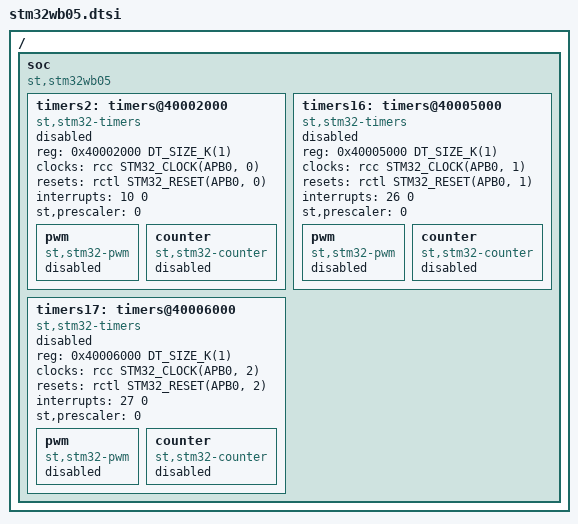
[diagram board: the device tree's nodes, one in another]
/*
 * Copyright (c) 2024 STMicroelectronics
 *
 * SPDX-License-Identifier: Apache-2.0
 */

#include <st/wb0/stm32wb0.dtsi>

/ {
	soc {
		compatible = "st,stm32wb05", "st,stm32wb0", "simple-bus";

		timers2: timers@40002000 {
			compatible = "st,stm32-timers";
			reg = <0x40002000 DT_SIZE_K(1)>;
			clocks = <&rcc STM32_CLOCK(APB0, 0)>;
			resets = <&rctl STM32_RESET(APB0, 0)>;
			interrupts = <10 0>;
			interrupt-names = "global";
			st,prescaler = <0>;
			status = "disabled";

			pwm {
				compatible = "st,stm32-pwm";
				status = "disabled";
				#pwm-cells = <3>;
			};

			counter {
				compatible = "st,stm32-counter";
				status = "disabled";
			};
		};

		timers16: timers@40005000 {
			compatible = "st,stm32-timers";
			reg = <0x40005000 DT_SIZE_K(1)>;
			clocks = <&rcc STM32_CLOCK(APB0, 1)>;
			resets = <&rctl STM32_RESET(APB0, 1)>;
			interrupts = <26 0>;
			interrupt-names = "global";
			st,prescaler = <0>;
			status = "disabled";

			pwm {
				compatible = "st,stm32-pwm";
				status = "disabled";
				#pwm-cells = <3>;
			};

			counter {
				compatible = "st,stm32-counter";
				status = "disabled";
			};
		};

		timers17: timers@40006000 {
			compatible = "st,stm32-timers";
			reg = <0x40006000 DT_SIZE_K(1)>;
			clocks = <&rcc STM32_CLOCK(APB0, 2)>;
			resets = <&rctl STM32_RESET(APB0, 2)>;
			interrupts = <27 0>;
			interrupt-names = "global";
			st,prescaler = <0>;
			status = "disabled";

			pwm {
				compatible = "st,stm32-pwm";
				status = "disabled";
				#pwm-cells = <3>;
			};

			counter {
				compatible = "st,stm32-counter";
				status = "disabled";
			};
		};
	};
};
